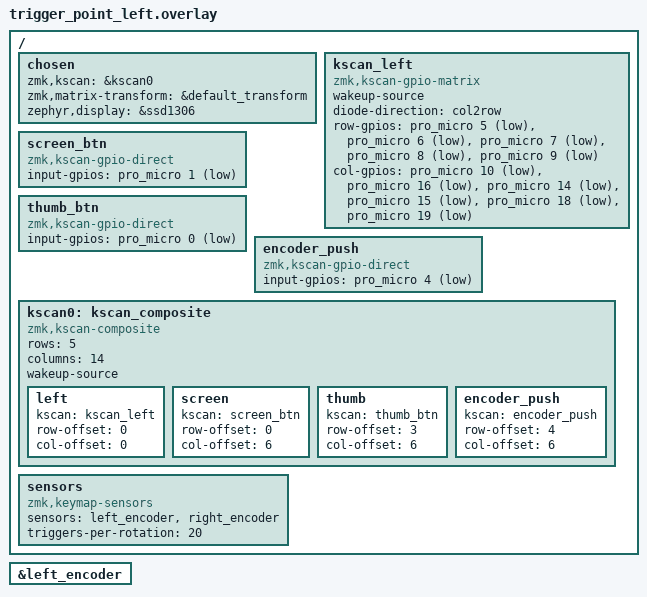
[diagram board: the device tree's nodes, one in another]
#include <dt-bindings/gpio/gpio.h>
#include "trigger_point.dtsi"
#include "trigger_point_split.dtsi"

/ {
	chosen {
		zmk,kscan = &kscan0;
        zmk,matrix-transform = &default_transform;
        zephyr,display = &ssd1306;
	};

	kscan_left: kscan_left {
		compatible = "zmk,kscan-gpio-matrix";
		wakeup-source;
		diode-direction = "col2row";

		row-gpios = <&pro_micro 5 (GPIO_ACTIVE_LOW | GPIO_PULL_UP)>,
		            <&pro_micro 6 (GPIO_ACTIVE_LOW | GPIO_PULL_UP)>,
		            <&pro_micro 7 (GPIO_ACTIVE_LOW | GPIO_PULL_UP)>,
		            <&pro_micro 8 (GPIO_ACTIVE_LOW | GPIO_PULL_UP)>,
		            <&pro_micro 9 (GPIO_ACTIVE_LOW | GPIO_PULL_UP)>;

		col-gpios = <&pro_micro 10 GPIO_ACTIVE_LOW>,
		            <&pro_micro 16 GPIO_ACTIVE_LOW>,
		            <&pro_micro 14 GPIO_ACTIVE_LOW>,
		            <&pro_micro 15 GPIO_ACTIVE_LOW>,
		            <&pro_micro 18 GPIO_ACTIVE_LOW>,
                    <&pro_micro 19 GPIO_ACTIVE_LOW>;
	};

	/* Three direct keys for column 6 at rows 0,3,4 */
	screen_btn: screen_btn {
		compatible = "zmk,kscan-gpio-direct";
		input-gpios = <&pro_micro 1 (GPIO_ACTIVE_LOW | GPIO_PULL_UP)>;
	};

	thumb_btn: thumb_btn {
		compatible = "zmk,kscan-gpio-direct";
		input-gpios = <&pro_micro 0 (GPIO_ACTIVE_LOW | GPIO_PULL_UP)>;
	};

	encoder_push: encoder_push {
		compatible = "zmk,kscan-gpio-direct";
		input-gpios = <&pro_micro 4 (GPIO_ACTIVE_LOW | GPIO_PULL_UP)>;
	};

	/* Composite scanner exposes one 5x14 matrix to match your keymap width */
	kscan0: kscan_composite {
		compatible = "zmk,kscan-composite";
		rows = <5>;
		columns = <14>;
		wakeup-source;

		left          { kscan = <&kscan_left>; row-offset = <0>; col-offset = <0>; };
		screen        { kscan = <&screen_btn>;   row-offset = <0>; col-offset = <6>; };
		thumb         { kscan = <&thumb_btn>;   row-offset = <3>; col-offset = <6>; };
		encoder_push  { kscan = <&encoder_push>;   row-offset = <4>; col-offset = <6>; };
		
	};
	sensors: sensors {
        compatible = "zmk,keymap-sensors";
        sensors = <&left_encoder &right_encoder>;
        triggers-per-rotation = <20>;
    };
};

&left_encoder {
	status = "okay";
};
